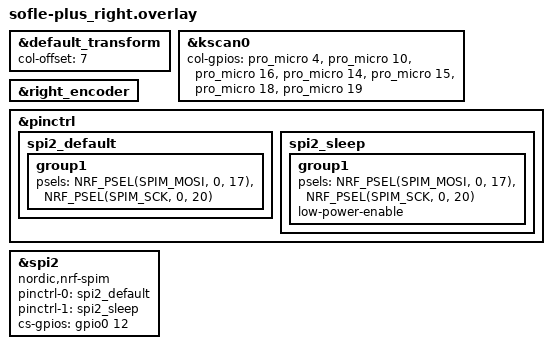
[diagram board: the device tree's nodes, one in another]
/*
 * Copyright (c) 2020 Ryan Cross
 *
 * SPDX-License-Identifier: MIT
 */

#include "sofle-plus.dtsi"

&default_transform {
    col-offset = <7>;
};

&kscan0 {
    col-gpios
        = <&pro_micro 4 GPIO_ACTIVE_HIGH>
        , <&pro_micro 10 GPIO_ACTIVE_HIGH>
        , <&pro_micro 16 GPIO_ACTIVE_HIGH>
        , <&pro_micro 14 GPIO_ACTIVE_HIGH>
        , <&pro_micro 15 GPIO_ACTIVE_HIGH>
        , <&pro_micro 18 GPIO_ACTIVE_HIGH>
        , <&pro_micro 19 GPIO_ACTIVE_HIGH>
        ;
};

&right_encoder {
    status = "okay";
};
&pinctrl {
    spi2_default: spi2_default {
        group1 {
            psels = <NRF_PSEL(SPIM_MOSI, 0, 17)>,
            <NRF_PSEL(SPIM_SCK, 0, 20)>;
        };
    };
    spi2_sleep: spi2_sleep {
        group1 {
            psels = <NRF_PSEL(SPIM_MOSI, 0, 17)>,
            <NRF_PSEL(SPIM_SCK, 0, 20)>;
            low-power-enable;
        };
    };
};
nice_view_spi: &spi2 {
    compatible = "nordic,nrf-spim";
    pinctrl-0 = <&spi2_default>;
    pinctrl-1 = <&spi2_sleep>;
    pinctrl-names = "default", "sleep";
    cs-gpios = <&gpio0 12 GPIO_ACTIVE_HIGH>;
};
